AUTOSAR XML (schema 00048)
package /ComponentTypes
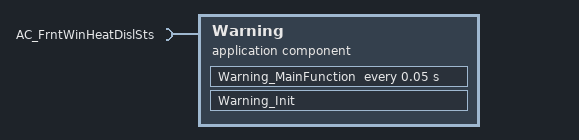
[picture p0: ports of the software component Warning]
  application sw component type Warning
    require port AC_FrntWinHeatDislSts: nonqueued-receiver-com-spec{data-element=AC_FrntWinHeatDislSts, alive-timeout=100, enable-update=true, filter=data-filter-type=ALWAYS, handle-never-received=true, init-value=0}, required-interface=AC_FrntWinHeatDislSts
    behavior Warning_InternalBehavior
      init event Warning_InitEvent: start-on-event=Warning_Init
      timing event TMT_Warning_MainFunction: start-on-event=Warning_MainFunction, period=0.05
      runnable Warning_Init
      runnable Warning_MainFunction
        data-receive-point-by-arguments:
          access REC_AC_FrntWinHeatDislSts_AC_FrntWinHeatDislSts: accessed-variable=AC_FrntWinHeatDislSts.AC_FrntWinHeatDislSts
  swc implementation Warning_Implementation: behavior=Warning_InternalBehavior
